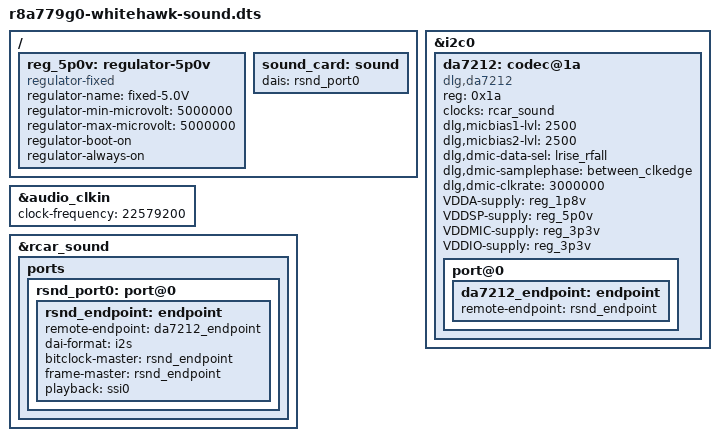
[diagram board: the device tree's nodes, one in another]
// SPDX-License-Identifier: GPL-2.0
/*
 * Device Tree Source for the White Hawk boards with R-Car V4H + ARD-AUDIO-DA7212 Board
 *
 * Copyright (C) 2022 Renesas Electronics Corp.
 */

/dts-v1/;
#include "r8a779g0-whitehawk.dts"

/ {
	reg_5p0v: regulator-5p0v {
			compatible = "regulator-fixed";
			regulator-name = "fixed-5.0V";
			regulator-min-microvolt = <5000000>;
			regulator-max-microvolt = <5000000>;
			regulator-boot-on;
			regulator-always-on;
	};

	sound_card: sound {
		dais = <&rsnd_port0>;	/* DA7212 Audio Codec */
	};
};

&i2c0 {
	da7212: codec@1a {
		compatible = "dlg,da7212";

		#sound-dai-cells = <0>;
		#address-cells = <1>;
		#size-cells = <0>;

		reg = <0x1a>;

		clocks = <&rcar_sound>;
		clock-names = "mclk";

		dlg,micbias1-lvl = <2500>;
		dlg,micbias2-lvl = <2500>;
		dlg,dmic-data-sel = "lrise_rfall";
		dlg,dmic-samplephase = "between_clkedge";
		dlg,dmic-clkrate = <3000000>;

		VDDA-supply = <&reg_1p8v>;
		VDDSP-supply = <&reg_5p0v>;
		VDDMIC-supply = <&reg_3p3v>;
		VDDIO-supply = <&reg_3p3v>;

		port@0 {
			da7212_endpoint: endpoint {
				remote-endpoint = <&rsnd_endpoint>;
			};
		};
	};
};

&audio_clkin {
	clock-frequency = <22579200>;
};

&rcar_sound {
	ports {
		rsnd_port0: port@0 {
			rsnd_endpoint: endpoint {
				remote-endpoint = <&da7212_endpoint>;

				dai-format = "i2s";
				bitclock-master = <&rsnd_endpoint>;
				frame-master = <&rsnd_endpoint>;

				/* Please use exclusively to the 'capture' */
				playback = <&ssi0>;
			};
		};
	};
};
